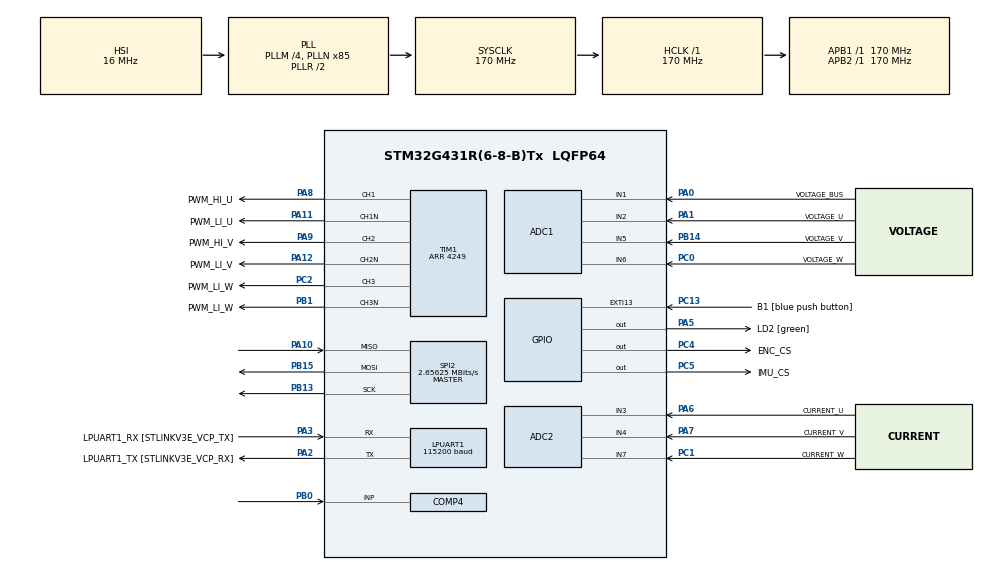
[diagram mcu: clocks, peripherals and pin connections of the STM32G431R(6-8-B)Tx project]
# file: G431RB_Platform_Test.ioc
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ADC1.Channel-0\#ChannelRegularConversion=ADC_CHANNEL_5
ADC1.ContinuousConvMode=ENABLE
ADC1.ExternalTrigConv=ADC_EXTERNALTRIG_T1_TRGO2
ADC1.NbrOfConversionFlag=1
ADC1.OffsetNumber-0\#ChannelRegularConversion=ADC_OFFSET_NONE
ADC1.Overrun=ADC_OVR_DATA_OVERWRITTEN
ADC1.Rank-0\#ChannelRegularConversion=1
ADC1.SamplingTime-0\#ChannelRegularConversion=ADC_SAMPLETIME_2CYCLES_5
ADC1.master=1
ADC2.Channel-0\#ChannelRegularConversion=ADC_CHANNEL_3
ADC2.ContinuousConvMode=ENABLE
ADC2.ExternalTrigConv=ADC_EXTERNALTRIG_T1_TRGO2
ADC2.NbrOfConversion=1
ADC2.NbrOfConversionFlag=1
ADC2.OffsetNumber-0\#ChannelRegularConversion=ADC_OFFSET_NONE
ADC2.Overrun=ADC_OVR_DATA_OVERWRITTEN
ADC2.OversamplingMode=DISABLE
ADC2.Rank-0\#ChannelRegularConversion=1
ADC2.SamplingTime-0\#ChannelRegularConversion=ADC_SAMPLETIME_2CYCLES_5
LPUART1.BaudRate=115200
LPUART1.WordLength=UART_WORDLENGTH_8B
Mcu.Family=STM32G4
Mcu.Name=STM32G431R(6-8-B)Tx
Mcu.Package=LQFP64
NVIC.ADC1_2_IRQn=true\:0\:0\:false\:false\:true\:true\:true\:true
NVIC.PriorityGroup=NVIC_PRIORITYGROUP_4
NVIC.SPI2_IRQn=true\:0\:0\:false\:false\:true\:true\:true\:true
NVIC.TIM1_BRK_TIM15_IRQn=true\:0\:0\:false\:false\:true\:true\:true\:true
NVIC.TIM1_CC_IRQn=true\:0\:0\:false\:false\:true\:true\:true\:true
NVIC.TIM1_TRG_COM_TIM17_IRQn=true\:0\:0\:false\:false\:true\:true\:true\:true
NVIC.TIM1_UP_TIM16_IRQn=true\:0\:0\:false\:false\:true\:true\:true\:true
NVIC.TIM3_IRQn=true\:0\:0\:false\:false\:true\:true\:true\:true
PA0.GPIO_Label=VOLTAGE_BUS
PA0.Mode=IN1-Single-Ended
PA0.Signal=ADC1_IN1
PA1.GPIO_Label=VOLTAGE_U
PA1.Mode=IN2-Single-Ended
PA1.Signal=ADC1_IN2
PA10.Mode=Full_Duplex_Master
PA10.Signal=SPI2_MISO
PA11.GPIO_Label=PWM_LI_U
PA11.Mode=PWM Generation1 CH1 CH1N
PA11.Signal=TIM1_CH1N
PA12.GPIO_Label=PWM_LI_V
PA12.Mode=PWM Generation2 CH2 CH2N
PA12.Signal=TIM1_CH2N
PA13.GPIO_Label=T_SWDIO
PA13.Mode=Serial_Wire
PA13.Signal=SYS_JTMS-SWDIO
PA14.GPIO_Label=T_SWCLK
PA14.Mode=Serial_Wire
PA14.Signal=SYS_JTCK-SWCLK
PA2.GPIO_Label=LPUART1_TX [STLINKV3E_VCP_RX]
PA2.Mode=Asynchronous
PA2.Signal=LPUART1_TX
PA3.GPIO_Label=LPUART1_RX [STLINKV3E_VCP_TX]
PA3.Mode=Asynchronous
PA3.Signal=LPUART1_RX
PA5.GPIO_Label=LD2 [green]
PA5.Signal=GPIO_Output
PA6.GPIO_Label=CURRENT_U
PA6.Mode=IN3-Single-Ended
PA6.Signal=ADC2_IN3
PA7.GPIO_Label=CURRENT_V
PA7.Mode=IN4-Single-Ended
PA7.Signal=ADC2_IN4
PA8.GPIO_Label=PWM_HI_U
PA8.Signal=S_TIM1_CH1
PA9.GPIO_Label=PWM_HI_V
PA9.Signal=S_TIM1_CH2
PB0.Signal=SharedAnalog_PB0
PB1.GPIO_Label=PWM_LI_W
PB1.Mode=PWM Generation3 CH3 CH3N
PB1.Signal=TIM1_CH3N
PB13.Mode=Full_Duplex_Master
PB13.Signal=SPI2_SCK
PB14.GPIO_Label=VOLTAGE_V
PB14.Mode=IN5-Single-Ended
PB14.Signal=ADC1_IN5
PB15.Mode=Full_Duplex_Master
PB15.Signal=SPI2_MOSI
PB3.GPIO_Label=T_SWO
PB3.Signal=SYS_JTDO-SWO
PC0.GPIO_Label=VOLTAGE_W
PC0.Mode=IN6-Single-Ended
PC0.Signal=ADC1_IN6
PC1.GPIO_Label=CURRENT_W
PC1.Mode=IN7-Single-Ended
PC1.Signal=ADC2_IN7
PC13.GPIO_Label=B1 [blue push button]
PC13.Signal=GPXTI13
PC14-OSC32_IN.Mode=LSE-External-Oscillator
PC14-OSC32_IN.Signal=RCC_OSC32_IN
PC15-OSC32_OUT.Mode=LSE-External-Oscillator
PC15-OSC32_OUT.Signal=RCC_OSC32_OUT
PC2.GPIO_Label=PWM_LI_W
PC2.Signal=S_TIM1_CH3
PC4.GPIO_Label=ENC_CS
PC4.Signal=GPIO_Output
PC5.GPIO_Label=IMU_CS
PC5.Signal=GPIO_Output
PF0-OSC_IN.Mode=HSE-External-Oscillator
PF0-OSC_IN.Signal=RCC_OSC_IN
PF1-OSC_OUT.Mode=HSE-External-Oscillator
PF1-OSC_OUT.Signal=RCC_OSC_OUT
ProjectManager.HeapSize=0x200
ProjectManager.StackSize=0x400
ProjectManager.TargetToolchain=STM32CubeIDE
RCC.ADC12Freq_Value=170000000
RCC.AHBFreq_Value=170000000
RCC.APB1Freq_Value=170000000
RCC.APB1TimFreq_Value=170000000
RCC.APB2Freq_Value=170000000
RCC.APB2TimFreq_Value=170000000
RCC.CortexFreq_Value=170000000
RCC.EXTERNAL_CLOCK_VALUE=12288000
RCC.HCLKFreq_Value=170000000
RCC.HSE_VALUE=24000000
RCC.HSI48_VALUE=48000000
RCC.HSI_VALUE=16000000
RCC.PLLM=RCC_PLLM_DIV4
RCC.PLLN=85
RCC.RTCClockSelection=RCC_RTCCLKSOURCE_LSE
RCC.SYSCLKFreq_VALUE=170000000
RCC.SYSCLKSource=RCC_SYSCLKSOURCE_PLLCLK
RCC.USBFreq_Value=170000000
RCC.VCOOutputFreq_Value=340000000
SH.S_TIM1_CH1.0=TIM1_CH1,PWM Generation1 CH1 CH1N
SH.S_TIM1_CH2.0=TIM1_CH2,PWM Generation2 CH2 CH2N
SH.S_TIM1_CH3.0=TIM1_CH3,PWM Generation3 CH3 CH3N
SH.SharedAnalog_PB0.0=OPAMP2_VINP
SH.SharedAnalog_PB0.1=COMP4_INP,INP
SPI2.BaudRatePrescaler=SPI_BAUDRATEPRESCALER_64
SPI2.CalculateBaudRate=2.65625 MBits/s
SPI2.DataSize=SPI_DATASIZE_16BIT
SPI2.Direction=SPI_DIRECTION_2LINES
SPI2.Mode=SPI_MODE_MASTER
SPI2.VirtualType=VM_MASTER
TIM1.AutoReloadPreload=TIM_AUTORELOAD_PRELOAD_ENABLE
TIM1.Channel-Output\ Compare5\ No\ Output=TIM_CHANNEL_5
TIM1.Channel-PWM\ Generation1\ CH1\ CH1N=TIM_CHANNEL_1
TIM1.Channel-PWM\ Generation2\ CH2\ CH2N=TIM_CHANNEL_2
TIM1.Channel-PWM\ Generation3\ CH3\ CH3N=TIM_CHANNEL_3
TIM1.CounterMode=TIM_COUNTERMODE_CENTERALIGNED1
TIM1.DeadTime=85
TIM1.PeriodNoDither=4249
TIM1.PulseNoDither_5=4249
TIM1.SourceBRKCOMP4=TIM_BREAKINPUTSOURCE_DISABLE
TIM1.TIM_MasterOutputTrigger2=TIM_TRGO2_OC5REF
TIM3.PeriodNoDither=99
TIM3.Prescaler=169
VP_COMP4_VS_VREFINT.Mode=VREFINT
VP_SYS_VS_DBSignals.Mode=DisableDeadBatterySignals
VP_TIM1_VS_ClockSourceINT.Mode=Internal
VP_TIM1_VS_ClockSourceITR.Mode=TriggerSource_ITR5
VP_TIM1_VS_ControllerModeTrigger.Mode=Trigger Mode
VP_TIM1_VS_no_output5.Mode=Output Compare5 No Output
VP_TIM3_VS_ClockSourceINT.Mode=Internal
board=NUCLEO-G431RB

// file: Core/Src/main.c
/* USER CODE BEGIN Header */
/**
  ******************************************************************************
  * @file           : main.c
  * @brief          : Main program body
  ******************************************************************************
  * @attention
  *
  * Copyright (c) 2026 STMicroelectronics.
  * All rights reserved.
  *
  * This software is licensed under terms that can be found in the LICENSE file
  * in the root directory of this software component.
  * If no LICENSE file comes with this software, it is provided AS-IS.
  *
  ******************************************************************************
  */
/* USER CODE END Header */
#include "main.h"

/* USER CODE BEGIN Includes */

#include "platform_data.h"
#include "timer.h"

/* USER CODE END Includes */

ADC_HandleTypeDef hadc1;
ADC_HandleTypeDef hadc2;

COMP_HandleTypeDef hcomp4;

UART_HandleTypeDef hlpuart1;

SPI_HandleTypeDef hspi2;

TIM_HandleTypeDef htim1;
TIM_HandleTypeDef htim3;

/* USER CODE BEGIN PV */
PlatformData_t motorData;

/* USER CODE END PV */

void SystemClock_Config(void);
static void MX_GPIO_Init(void);
static void MX_LPUART1_UART_Init(void);
static void MX_ADC1_Init(void);
static void MX_ADC2_Init(void);
static void MX_COMP4_Init(void);
static void MX_SPI2_Init(void);
static void MX_TIM1_Init(void);
static void MX_TIM3_Init(void);

int main(void)
{

  /* MCU Configuration--------------------------------------------------------*/

  /* Reset of all peripherals, Initializes the Flash interface and the Systick. */
  HAL_Init();

  /* Configure the system clock */
  SystemClock_Config();

  /* Initialize all configured peripherals */
  MX_GPIO_Init();
  MX_LPUART1_UART_Init();
  MX_ADC1_Init();
  MX_ADC2_Init();
  MX_COMP4_Init();
  MX_SPI2_Init();
  MX_TIM1_Init();
  MX_TIM3_Init();

  /* Infinite loop */
  while (1)
  {

  }
}

void SystemClock_Config(void)
{
  RCC_OscInitTypeDef RCC_OscInitStruct = {0};
  RCC_ClkInitTypeDef RCC_ClkInitStruct = {0};

  /** Configure the main internal regulator output voltage
  */
  HAL_PWREx_ControlVoltageScaling(PWR_REGULATOR_VOLTAGE_SCALE1_BOOST);

  /** Initializes the RCC Oscillators according to the specified parameters
  * in the RCC_OscInitTypeDef structure.
  */
  RCC_OscInitStruct.OscillatorType = RCC_OSCILLATORTYPE_HSI;
  RCC_OscInitStruct.HSIState = RCC_HSI_ON;
  RCC_OscInitStruct.HSICalibrationValue = RCC_HSICALIBRATION_DEFAULT;
  RCC_OscInitStruct.PLL.PLLState = RCC_PLL_ON;
  RCC_OscInitStruct.PLL.PLLSource = RCC_PLLSOURCE_HSI;
  RCC_OscInitStruct.PLL.PLLM = RCC_PLLM_DIV4;
  RCC_OscInitStruct.PLL.PLLN = 85;
  RCC_OscInitStruct.PLL.PLLP = RCC_PLLP_DIV2;
  RCC_OscInitStruct.PLL.PLLQ = RCC_PLLQ_DIV2;
  RCC_OscInitStruct.PLL.PLLR = RCC_PLLR_DIV2;
  if (HAL_RCC_OscConfig(&RCC_OscInitStruct) != HAL_OK)
  {
    Error_Handler();
  }

  /** Initializes the CPU, AHB and APB buses clocks
  */
  RCC_ClkInitStruct.ClockType = RCC_CLOCKTYPE_HCLK|RCC_CLOCKTYPE_SYSCLK
                              |RCC_CLOCKTYPE_PCLK1|RCC_CLOCKTYPE_PCLK2;
  RCC_ClkInitStruct.SYSCLKSource = RCC_SYSCLKSOURCE_PLLCLK;
  RCC_ClkInitStruct.AHBCLKDivider = RCC_SYSCLK_DIV1;
  RCC_ClkInitStruct.APB1CLKDivider = RCC_HCLK_DIV1;
  RCC_ClkInitStruct.APB2CLKDivider = RCC_HCLK_DIV1;

  if (HAL_RCC_ClockConfig(&RCC_ClkInitStruct, FLASH_LATENCY_4) != HAL_OK)
  {
    Error_Handler();
  }
}

static void MX_ADC1_Init(void)
{

  ADC_MultiModeTypeDef multimode = {0};
  ADC_ChannelConfTypeDef sConfig = {0};

  /** Common config
  */
  hadc1.Instance = ADC1;
  hadc1.Init.ClockPrescaler = ADC_CLOCK_SYNC_PCLK_DIV4;
  hadc1.Init.Resolution = ADC_RESOLUTION_12B;
  hadc1.Init.DataAlign = ADC_DATAALIGN_RIGHT;
  hadc1.Init.GainCompensation = 0;
  hadc1.Init.ScanConvMode = ADC_SCAN_DISABLE;
  hadc1.Init.EOCSelection = ADC_EOC_SINGLE_CONV;
  hadc1.Init.LowPowerAutoWait = DISABLE;
  hadc1.Init.ContinuousConvMode = ENABLE;
  hadc1.Init.NbrOfConversion = 1;
  hadc1.Init.DiscontinuousConvMode = DISABLE;
  hadc1.Init.ExternalTrigConv = ADC_EXTERNALTRIG_T1_TRGO2;
  hadc1.Init.ExternalTrigConvEdge = ADC_EXTERNALTRIGCONVEDGE_RISING;
  hadc1.Init.DMAContinuousRequests = DISABLE;
  hadc1.Init.Overrun = ADC_OVR_DATA_OVERWRITTEN;
  hadc1.Init.OversamplingMode = DISABLE;
  if (HAL_ADC_Init(&hadc1) != HAL_OK)
  {
    Error_Handler();
  }

  /** Configure the ADC multi-mode
  */
  multimode.Mode = ADC_MODE_INDEPENDENT;
  if (HAL_ADCEx_MultiModeConfigChannel(&hadc1, &multimode) != HAL_OK)
  {
    Error_Handler();
  }

  /** Configure Regular Channel
  */
  sConfig.Channel = ADC_CHANNEL_5;
  sConfig.Rank = ADC_REGULAR_RANK_1;
  sConfig.SamplingTime = ADC_SAMPLETIME_2CYCLES_5;
  sConfig.SingleDiff = ADC_SINGLE_ENDED;
  sConfig.OffsetNumber = ADC_OFFSET_NONE;
  sConfig.Offset = 0;
  if (HAL_ADC_ConfigChannel(&hadc1, &sConfig) != HAL_OK)
  {
    Error_Handler();
  }

}

static void MX_ADC2_Init(void)
{

  ADC_ChannelConfTypeDef sConfig = {0};

  /** Common config
  */
  hadc2.Instance = ADC2;
  hadc2.Init.ClockPrescaler = ADC_CLOCK_SYNC_PCLK_DIV4;
  hadc2.Init.Resolution = ADC_RESOLUTION_12B;
  hadc2.Init.DataAlign = ADC_DATAALIGN_RIGHT;
  hadc2.Init.GainCompensation = 0;
  hadc2.Init.ScanConvMode = ADC_SCAN_DISABLE;
  hadc2.Init.EOCSelection = ADC_EOC_SINGLE_CONV;
  hadc2.Init.LowPowerAutoWait = DISABLE;
  hadc2.Init.ContinuousConvMode = ENABLE;
  hadc2.Init.NbrOfConversion = 1;
  hadc2.Init.DiscontinuousConvMode = DISABLE;
  hadc2.Init.ExternalTrigConv = ADC_EXTERNALTRIG_T1_TRGO2;
  hadc2.Init.ExternalTrigConvEdge = ADC_EXTERNALTRIGCONVEDGE_RISING;
  hadc2.Init.DMAContinuousRequests = DISABLE;
  hadc2.Init.Overrun = ADC_OVR_DATA_OVERWRITTEN;
  hadc2.Init.OversamplingMode = DISABLE;
  if (HAL_ADC_Init(&hadc2) != HAL_OK)
  {
    Error_Handler();
  }

  /** Configure Regular Channel
  */
  sConfig.Channel = ADC_CHANNEL_3;
  sConfig.Rank = ADC_REGULAR_RANK_1;
  sConfig.SamplingTime = ADC_SAMPLETIME_2CYCLES_5;
  sConfig.SingleDiff = ADC_SINGLE_ENDED;
  sConfig.OffsetNumber = ADC_OFFSET_NONE;
  sConfig.Offset = 0;
  if (HAL_ADC_ConfigChannel(&hadc2, &sConfig) != HAL_OK)
  {
    Error_Handler();
  }

}

static void MX_COMP4_Init(void)
{

  hcomp4.Instance = COMP4;
  hcomp4.Init.InputPlus = COMP_INPUT_PLUS_IO1;
  hcomp4.Init.InputMinus = COMP_INPUT_MINUS_VREFINT;
  hcomp4.Init.OutputPol = COMP_OUTPUTPOL_NONINVERTED;
  hcomp4.Init.Hysteresis = COMP_HYSTERESIS_NONE;
  hcomp4.Init.BlankingSrce = COMP_BLANKINGSRC_NONE;
  hcomp4.Init.TriggerMode = COMP_TRIGGERMODE_NONE;
  if (HAL_COMP_Init(&hcomp4) != HAL_OK)
  {
    Error_Handler();
  }

}

static void MX_LPUART1_UART_Init(void)
{

  hlpuart1.Instance = LPUART1;
  hlpuart1.Init.BaudRate = 115200;
  hlpuart1.Init.WordLength = UART_WORDLENGTH_8B;
  hlpuart1.Init.StopBits = UART_STOPBITS_1;
  hlpuart1.Init.Parity = UART_PARITY_NONE;
  hlpuart1.Init.Mode = UART_MODE_TX_RX;
  hlpuart1.Init.HwFlowCtl = UART_HWCONTROL_NONE;
  hlpuart1.Init.OneBitSampling = UART_ONE_BIT_SAMPLE_DISABLE;
  hlpuart1.Init.ClockPrescaler = UART_PRESCALER_DIV1;
  hlpuart1.AdvancedInit.AdvFeatureInit = UART_ADVFEATURE_NO_INIT;
  if (HAL_UART_Init(&hlpuart1) != HAL_OK)
  {
    Error_Handler();
  }
  if (HAL_UARTEx_SetTxFifoThreshold(&hlpuart1, UART_TXFIFO_THRESHOLD_1_8) != HAL_OK)
  {
    Error_Handler();
  }
  if (HAL_UARTEx_SetRxFifoThreshold(&hlpuart1, UART_RXFIFO_THRESHOLD_1_8) != HAL_OK)
  {
    Error_Handler();
  }
  if (HAL_UARTEx_DisableFifoMode(&hlpuart1) != HAL_OK)
  {
    Error_Handler();
  }

}

static void MX_SPI2_Init(void)
{

  /* SPI2 parameter configuration*/
  hspi2.Instance = SPI2;
  hspi2.Init.Mode = SPI_MODE_MASTER;
  hspi2.Init.Direction = SPI_DIRECTION_2LINES;
  hspi2.Init.DataSize = SPI_DATASIZE_16BIT;
  hspi2.Init.CLKPolarity = SPI_POLARITY_LOW;
  hspi2.Init.CLKPhase = SPI_PHASE_1EDGE;
  hspi2.Init.NSS = SPI_NSS_SOFT;
  hspi2.Init.BaudRatePrescaler = SPI_BAUDRATEPRESCALER_64;
  hspi2.Init.FirstBit = SPI_FIRSTBIT_MSB;
  hspi2.Init.TIMode = SPI_TIMODE_DISABLE;
  hspi2.Init.CRCCalculation = SPI_CRCCALCULATION_DISABLE;
  hspi2.Init.CRCPolynomial = 7;
  hspi2.Init.CRCLength = SPI_CRC_LENGTH_DATASIZE;
  hspi2.Init.NSSPMode = SPI_NSS_PULSE_ENABLE;
  if (HAL_SPI_Init(&hspi2) != HAL_OK)
  {
    Error_Handler();
  }

}

static void MX_TIM1_Init(void)
{

  TIM_ClockConfigTypeDef sClockSourceConfig = {0};
  TIM_SlaveConfigTypeDef sSlaveConfig = {0};
  TIM_MasterConfigTypeDef sMasterConfig = {0};
  TIM_OC_InitTypeDef sConfigOC = {0};
  TIM_BreakDeadTimeConfigTypeDef sBreakDeadTimeConfig = {0};

  htim1.Instance = TIM1;
  htim1.Init.Prescaler = 0;
  htim1.Init.CounterMode = TIM_COUNTERMODE_CENTERALIGNED1;
  htim1.Init.Period = 4249;
  htim1.Init.ClockDivision = TIM_CLOCKDIVISION_DIV1;
  htim1.Init.RepetitionCounter = 0;
  htim1.Init.AutoReloadPreload = TIM_AUTORELOAD_PRELOAD_ENABLE;
  if (HAL_TIM_Base_Init(&htim1) != HAL_OK)
  {
    Error_Handler();
  }
  sClockSourceConfig.ClockSource = TIM_CLOCKSOURCE_INTERNAL;
  if (HAL_TIM_ConfigClockSource(&htim1, &sClockSourceConfig) != HAL_OK)
  {
    Error_Handler();
  }
  if (HAL_TIM_PWM_Init(&htim1) != HAL_OK)
  {
    Error_Handler();
  }
  if (HAL_TIM_OC_Init(&htim1) != HAL_OK)
  {
    Error_Handler();
  }
  sSlaveConfig.SlaveMode = TIM_SLAVEMODE_TRIGGER;
  sSlaveConfig.InputTrigger = TIM_TS_ITR5;
  if (HAL_TIM_SlaveConfigSynchro(&htim1, &sSlaveConfig) != HAL_OK)
  {
    Error_Handler();
  }
  sMasterConfig.MasterOutputTrigger = TIM_TRGO_RESET;
  sMasterConfig.MasterOutputTrigger2 = TIM_TRGO2_OC5REF;
  sMasterConfig.MasterSlaveMode = TIM_MASTERSLAVEMODE_DISABLE;
  if (HAL_TIMEx_MasterConfigSynchronization(&htim1, &sMasterConfig) != HAL_OK)
  {
    Error_Handler();
  }
  sConfigOC.OCMode = TIM_OCMODE_PWM1;
  sConfigOC.Pulse = 0;
  sConfigOC.OCPolarity = TIM_OCPOLARITY_HIGH;
  sConfigOC.OCNPolarity = TIM_OCNPOLARITY_HIGH;
  sConfigOC.OCFastMode = TIM_OCFAST_DISABLE;
  sConfigOC.OCIdleState = TIM_OCIDLESTATE_RESET;
  sConfigOC.OCNIdleState = TIM_OCNIDLESTATE_RESET;
  if (HAL_TIM_PWM_ConfigChannel(&htim1, &sConfigOC, TIM_CHANNEL_1) != HAL_OK)
  {
    Error_Handler();
  }
  if (HAL_TIM_PWM_ConfigChannel(&htim1, &sConfigOC, TIM_CHANNEL_2) != HAL_OK)
  {
    Error_Handler();
  }
  if (HAL_TIM_PWM_ConfigChannel(&htim1, &sConfigOC, TIM_CHANNEL_3) != HAL_OK)
  {
    Error_Handler();
  }
  sConfigOC.OCMode = TIM_OCMODE_TIMING;
  sConfigOC.Pulse = 4249;
  if (HAL_TIM_OC_ConfigChannel(&htim1, &sConfigOC, TIM_CHANNEL_5) != HAL_OK)
  {
    Error_Handler();
  }
  sBreakDeadTimeConfig.OffStateRunMode = TIM_OSSR_DISABLE;
  sBreakDeadTimeConfig.OffStateIDLEMode = TIM_OSSI_DISABLE;
  sBreakDeadTimeConfig.LockLevel = TIM_LOCKLEVEL_OFF;
  sBreakDeadTimeConfig.DeadTime = 85;
  sBreakDeadTimeConfig.BreakState = TIM_BREAK_DISABLE;
  sBreakDeadTimeConfig.BreakPolarity = TIM_BREAKPOLARITY_HIGH;
  sBreakDeadTimeConfig.BreakFilter = 0;
  sBreakDeadTimeConfig.BreakAFMode = TIM_BREAK_AFMODE_INPUT;
  sBreakDeadTimeConfig.Break2State = TIM_BREAK2_DISABLE;
  sBreakDeadTimeConfig.Break2Polarity = TIM_BREAK2POLARITY_HIGH;
  sBreakDeadTimeConfig.Break2Filter = 0;
  sBreakDeadTimeConfig.Break2AFMode = TIM_BREAK_AFMODE_INPUT;
  sBreakDeadTimeConfig.AutomaticOutput = TIM_AUTOMATICOUTPUT_DISABLE;
  if (HAL_TIMEx_ConfigBreakDeadTime(&htim1, &sBreakDeadTimeConfig) != HAL_OK)
  {
    Error_Handler();
  }
  HAL_TIM_MspPostInit(&htim1);

}

static void MX_TIM3_Init(void)
{

  TIM_ClockConfigTypeDef sClockSourceConfig = {0};
  TIM_MasterConfigTypeDef sMasterConfig = {0};

  htim3.Instance = TIM3;
  htim3.Init.Prescaler = 169;
  htim3.Init.CounterMode = TIM_COUNTERMODE_UP;
  htim3.Init.Period = 99;
  htim3.Init.ClockDivision = TIM_CLOCKDIVISION_DIV1;
  htim3.Init.AutoReloadPreload = TIM_AUTORELOAD_PRELOAD_DISABLE;
  if (HAL_TIM_Base_Init(&htim3) != HAL_OK)
  {
    Error_Handler();
  }
  sClockSourceConfig.ClockSource = TIM_CLOCKSOURCE_INTERNAL;
  if (HAL_TIM_ConfigClockSource(&htim3, &sClockSourceConfig) != HAL_OK)
  {
    Error_Handler();
  }
  sMasterConfig.MasterOutputTrigger = TIM_TRGO_RESET;
  sMasterConfig.MasterSlaveMode = TIM_MASTERSLAVEMODE_DISABLE;
  if (HAL_TIMEx_MasterConfigSynchronization(&htim3, &sMasterConfig) != HAL_OK)
  {
    Error_Handler();
  }

}

static void MX_GPIO_Init(void)
{
  GPIO_InitTypeDef GPIO_InitStruct = {0};

  /* GPIO Ports Clock Enable */
  __HAL_RCC_GPIOC_CLK_ENABLE();
  __HAL_RCC_GPIOF_CLK_ENABLE();
  __HAL_RCC_GPIOA_CLK_ENABLE();
  __HAL_RCC_GPIOB_CLK_ENABLE();

  /*Configure GPIO pin Output Level */
  HAL_GPIO_WritePin(LD2_GPIO_Port, LD2_Pin, GPIO_PIN_RESET);

  /*Configure GPIO pin Output Level */
  HAL_GPIO_WritePin(GPIOC, ENC_CS_Pin|IMU_CS_Pin, GPIO_PIN_RESET);

  /*Configure GPIO pin : B1_Pin */
  GPIO_InitStruct.Pin = B1_Pin;
  GPIO_InitStruct.Mode = GPIO_MODE_IT_RISING;
  GPIO_InitStruct.Pull = GPIO_NOPULL;
  HAL_GPIO_Init(B1_GPIO_Port, &GPIO_InitStruct);

  /*Configure GPIO pin : LD2_Pin */
  GPIO_InitStruct.Pin = LD2_Pin;
  GPIO_InitStruct.Mode = GPIO_MODE_OUTPUT_PP;
  GPIO_InitStruct.Pull = GPIO_NOPULL;
  GPIO_InitStruct.Speed = GPIO_SPEED_FREQ_LOW;
  HAL_GPIO_Init(LD2_GPIO_Port, &GPIO_InitStruct);

  /*Configure GPIO pins : ENC_CS_Pin IMU_CS_Pin */
  GPIO_InitStruct.Pin = ENC_CS_Pin|IMU_CS_Pin;
  GPIO_InitStruct.Mode = GPIO_MODE_OUTPUT_PP;
  GPIO_InitStruct.Pull = GPIO_NOPULL;
  GPIO_InitStruct.Speed = GPIO_SPEED_FREQ_LOW;
  HAL_GPIO_Init(GPIOC, &GPIO_InitStruct);

  /*Configure GPIO pin : PB0 */
  GPIO_InitStruct.Pin = GPIO_PIN_0;
  GPIO_InitStruct.Mode = GPIO_MODE_ANALOG;
  GPIO_InitStruct.Pull = GPIO_NOPULL;
  HAL_GPIO_Init(GPIOB, &GPIO_InitStruct);

}

/* USER CODE BEGIN 4 */

void HAL_TIM_PeriodElapsedCallback(TIM_HandleTypeDef *htim) {
	if (htim == &htim3) {
		tim3_task(&hlpuart1, &motorData);
	}
}

/* USER CODE END 4 */

void Error_Handler(void)
{
  __disable_irq();
  while (1)
  {
  }
}
